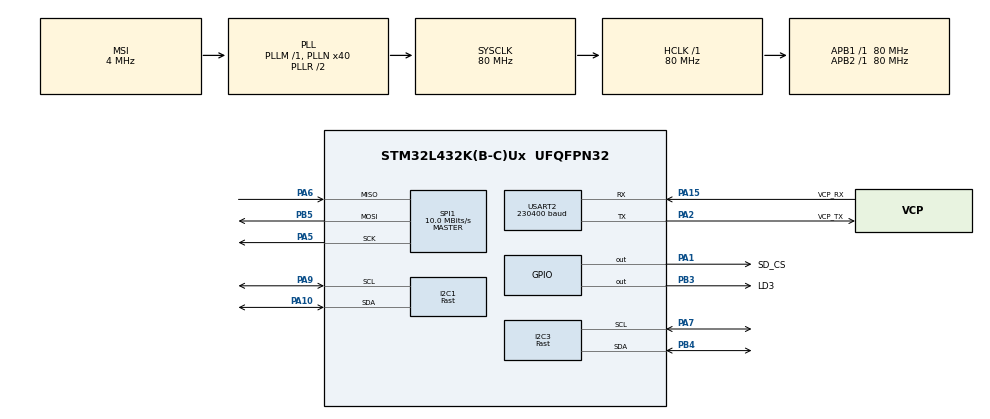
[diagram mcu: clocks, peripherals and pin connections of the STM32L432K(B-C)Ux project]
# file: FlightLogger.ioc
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Mcu.Family=STM32L4
PA6.Mode=Full_Duplex_Master
RCC.CortexFreq_Value=80000000
I2C1.I2C_Speed_Mode=I2C_Fast
SPI1.VirtualType=VM_MASTER
NVIC.TIM6_DAC_IRQn=true\:0\:0\:false\:false\:true\:true\:true
PA0.GPIO_Label=MCO [High speed clock in]
VP_SYS_VS_tim16.Mode=TIM16
PA15\ (JTDI).Signal=USART2_RX
PC15-OSC32_OUT\ (PC15).Mode=LSE-External-Oscillator
RCC.SYSCLKSource=RCC_SYSCLKSOURCE_PLLCLK
ProjectManager.StackSize=0x400
PB3\ (JTDO-TRACESWO).Signal=GPIO_Output
PC14-OSC32_IN\ (PC14).Mode=LSE-External-Oscillator
PA14\ (JTCK-SWCLK).Signal=SYS_JTCK-SWCLK
PA15\ (JTDI).Mode=Asynchronous
SPI1.Direction=SPI_DIRECTION_2LINES
RCC.HCLKFreq_Value=80000000
RCC.APB2TimFreq_Value=80000000
SPI1.CalculateBaudRate=10.0 MBits/s
RCC.AHBFreq_Value=80000000
RCC.HSE_VALUE=8000000
USART2.VirtualMode-Asynchronous=VM_ASYNC
RCC.PLLMUL=RCC_PLLMUL_4
PB5.Mode=Full_Duplex_Master
SPI1.DataSize=SPI_DATASIZE_8BIT
PA0.Mode=HSE-External-Clock-Source-for-LittleOrca
TIM6.Period=1
PA0.Signal=RCC_CK_IN
Mcu.Package=UFQFPN32
PA6.Signal=SPI1_MISO
NVIC.TimeBase=TIM1_UP_TIM16_IRQn
PA2.GPIO_Label=VCP_TX
NVIC.TimeBaseIP=TIM16
PA10.Signal=I2C1_SDA
I2C3.Timing=0x00702991
RCC.APB1TimFreq_Value=80000000
PA13\ (JTMS-SWDIO).Signal=SYS_JTMS-SWDIO
SPI1.BaudRatePrescaler=SPI_BAUDRATEPRESCALER_8
RCC.HSI48_VALUE=48000000
PA5.Mode=Full_Duplex_Master
RCC.MSI_VALUE=4000000
PA14\ (JTCK-SWCLK).Mode=Serial_Wire
PA7.Mode=I2C
PA10.Mode=I2C
TIM6.Prescaler=80-1
VP_TIM6_VS_ClockSourceINT.Mode=Enable_Timer
PC15-OSC32_OUT\ (PC15).Signal=RCC_OSC32_OUT
PA14\ (JTCK-SWCLK).GPIO_Label=SWCLK
PB3\ (JTDO-TRACESWO).GPIO_Label=LD3
USART2.BaudRate=230400
RCC.HSI16_VALUE=16000000
TIM6.AutoReloadPreload=TIM_AUTORELOAD_PRELOAD_DISABLE
PA9.Mode=I2C
ProjectManager.TargetToolchain=STM32CubeIDE
PA9.Signal=I2C1_SCL
I2C1.Timing=0x00702991
PA1.Signal=GPIO_Output
VP_FATFS_VS_Generic.Mode=User_defined
PA5.Signal=SPI1_SCK
board=NUCLEO-L432KC
RCC.VCOOutputFreq_Value=160000000
RCC.APB2Freq_Value=80000000
PA13\ (JTMS-SWDIO).GPIO_Label=SWDIO
SPI1.Mode=SPI_MODE_MASTER
PA1.GPIO_Label=SD_CS
PB4\ (NJTRST).Mode=I2C
PA15\ (JTDI).GPIO_Label=VCP_RX
Mcu.Name=STM32L432K(B-C)Ux
PA2.Signal=USART2_TX
PA13\ (JTMS-SWDIO).Mode=Serial_Wire
RCC.SYSCLKFreq_VALUE=80000000
PB5.Signal=SPI1_MOSI
PC14-OSC32_IN\ (PC14).Signal=RCC_OSC32_IN
ProjectManager.HeapSize=0x200
RCC.HSI_VALUE=16000000
NVIC.TIM1_UP_TIM16_IRQn=true\:0\:0\:false\:false\:true\:false\:true
NVIC.PriorityGroup=NVIC_PRIORITYGROUP_4
RCC.PLLN=40
PA2.Mode=Asynchronous
RCC.APB1Freq_Value=80000000
PA7.Signal=I2C3_SCL
I2C3.I2C_Speed_Mode=I2C_Fast
PB4\ (NJTRST).Signal=I2C3_SDA

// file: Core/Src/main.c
/* USER CODE BEGIN Header */
/**
  ******************************************************************************
  * @file           : main.c
  * @brief          : Main program body
  ******************************************************************************
  * @attention
  *
  * <h2><center>&copy; Copyright (c) 2021 STMicroelectronics.
  * All rights reserved.</center></h2>
  *
  * This software component is licensed by ST under BSD 3-Clause license,
  * the "License"; You may not use this file except in compliance with the
  * License. You may obtain a copy of the License at:
  *                        opensource.org/licenses/BSD-3-Clause
  *
  ******************************************************************************
  */
/* USER CODE END Header */
#include "main.h"
#include "fatfs.h"
#include "i2c.h"
#include "spi.h"
#include "tim.h"
#include "usart.h"
#include "gpio.h"

/* USER CODE BEGIN Includes */
#include <stdint.h>
#include <stdbool.h>
#include "sd_hal_mpu6050.h"
#include "string.h"
#include "Application.h"
/* USER CODE END Includes */

/* USER CODE BEGIN PV */
volatile uint32_t u32usTick = 0;
/* USER CODE END PV */

void SystemClock_Config(void);

int main(void)
{

  /* MCU Configuration--------------------------------------------------------*/

  /* Reset of all peripherals, Initializes the Flash interface and the Systick. */
  HAL_Init();

  /* Configure the system clock */
  SystemClock_Config();

  /* Initialize all configured peripherals */
  MX_GPIO_Init();
  MX_USART2_UART_Init();
  MX_I2C1_Init();
  MX_SPI1_Init();
  MX_FATFS_Init();
  MX_I2C3_Init();
  MX_TIM6_Init();
  /* USER CODE BEGIN 2 */

  //HAL_TIM_Base_Start_IT(&htim6);

  ApplicationInit();

  /* USER CODE END 2 */

  /* Infinite loop */
  while (1)
  {

    /* USER CODE BEGIN 3 */
	  ApplicationTask();
  }
  /* USER CODE END 3 */
}

void SystemClock_Config(void)
{
  RCC_OscInitTypeDef RCC_OscInitStruct = {0};
  RCC_ClkInitTypeDef RCC_ClkInitStruct = {0};
  RCC_PeriphCLKInitTypeDef PeriphClkInit = {0};

  /** Configure LSE Drive Capability
  */
  HAL_PWR_EnableBkUpAccess();
  __HAL_RCC_LSEDRIVE_CONFIG(RCC_LSEDRIVE_LOW);
  /** Initializes the RCC Oscillators according to the specified parameters
  * in the RCC_OscInitTypeDef structure.
  */
  RCC_OscInitStruct.OscillatorType = RCC_OSCILLATORTYPE_LSE|RCC_OSCILLATORTYPE_MSI;
  RCC_OscInitStruct.LSEState = RCC_LSE_ON;
  RCC_OscInitStruct.MSIState = RCC_MSI_ON;
  RCC_OscInitStruct.MSICalibrationValue = 0;
  RCC_OscInitStruct.MSIClockRange = RCC_MSIRANGE_6;
  RCC_OscInitStruct.PLL.PLLState = RCC_PLL_ON;
  RCC_OscInitStruct.PLL.PLLSource = RCC_PLLSOURCE_MSI;
  RCC_OscInitStruct.PLL.PLLM = 1;
  RCC_OscInitStruct.PLL.PLLN = 40;
  RCC_OscInitStruct.PLL.PLLP = RCC_PLLP_DIV7;
  RCC_OscInitStruct.PLL.PLLQ = RCC_PLLQ_DIV2;
  RCC_OscInitStruct.PLL.PLLR = RCC_PLLR_DIV2;
  if (HAL_RCC_OscConfig(&RCC_OscInitStruct) != HAL_OK)
  {
    Error_Handler();
  }
  /** Initializes the CPU, AHB and APB buses clocks
  */
  RCC_ClkInitStruct.ClockType = RCC_CLOCKTYPE_HCLK|RCC_CLOCKTYPE_SYSCLK
                              |RCC_CLOCKTYPE_PCLK1|RCC_CLOCKTYPE_PCLK2;
  RCC_ClkInitStruct.SYSCLKSource = RCC_SYSCLKSOURCE_PLLCLK;
  RCC_ClkInitStruct.AHBCLKDivider = RCC_SYSCLK_DIV1;
  RCC_ClkInitStruct.APB1CLKDivider = RCC_HCLK_DIV1;
  RCC_ClkInitStruct.APB2CLKDivider = RCC_HCLK_DIV1;

  if (HAL_RCC_ClockConfig(&RCC_ClkInitStruct, FLASH_LATENCY_4) != HAL_OK)
  {
    Error_Handler();
  }
  PeriphClkInit.PeriphClockSelection = RCC_PERIPHCLK_USART2|RCC_PERIPHCLK_I2C1
                              |RCC_PERIPHCLK_I2C3;
  PeriphClkInit.Usart2ClockSelection = RCC_USART2CLKSOURCE_PCLK1;
  PeriphClkInit.I2c1ClockSelection = RCC_I2C1CLKSOURCE_PCLK1;
  PeriphClkInit.I2c3ClockSelection = RCC_I2C3CLKSOURCE_PCLK1;
  if (HAL_RCCEx_PeriphCLKConfig(&PeriphClkInit) != HAL_OK)
  {
    Error_Handler();
  }
  /** Configure the main internal regulator output voltage
  */
  if (HAL_PWREx_ControlVoltageScaling(PWR_REGULATOR_VOLTAGE_SCALE1) != HAL_OK)
  {
    Error_Handler();
  }
  /** Enable MSI Auto calibration
  */
  HAL_RCCEx_EnableMSIPLLMode();
}

 /**
  * @brief  Period elapsed callback in non blocking mode
  * @note   This function is called  when TIM16 interrupt took place, inside
  * HAL_TIM_IRQHandler(). It makes a direct call to HAL_IncTick() to increment
  * a global variable "uwTick" used as application time base.
  * @param  htim : TIM handle
  * @retval None
  */
void HAL_TIM_PeriodElapsedCallback(TIM_HandleTypeDef *htim)
{
  if (htim->Instance == TIM16) {
    HAL_IncTick();
  }
  /* USER CODE BEGIN Callback 1 */

  if(htim->Instance == TIM6) {
	  u32usTick++;
  }
  /* USER CODE END Callback 1 */
}

void Error_Handler(void)
{
  __disable_irq();
  while (1)
  {
  }
}

/************************ (C) COPYRIGHT STMicroelectronics *****END OF FILE****/
